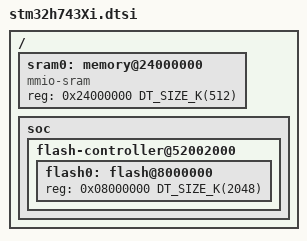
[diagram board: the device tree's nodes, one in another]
/*
 * Copyright (c) 2019 SEAL AG
 *
 * SPDX-License-Identifier: Apache-2.0
 */

#include <mem.h>
#include <st/h7/stm32h743.dtsi>

/ {
	sram0: memory@24000000 {
		reg = <0x24000000 DT_SIZE_K(512)>;
		compatible = "mmio-sram";
	};

	soc {
		flash-controller@52002000 {
			flash0: flash@8000000 {
				reg = <0x08000000 DT_SIZE_K(2048)>;
			};
		};
	};
};
